# EVTSVT register map
Vendor: Texas Instruments
Peripheral module from a debugger description file (folder CC23x0R5).
Registers are 32-bit, access per field, reset 0x0 unless marked. A register's access mark holds for its fields unless they carry their own. Offsets are as the file gives them; lines under a group give offsets from that group; [hi:lo] are bit positions; {n}, {i} and the like mark numbered series; 'fields as' and 'values as' point back to an identical list; <NAME> marks a mode.

## EVTSVT — This is top module of SVT Event Fabric
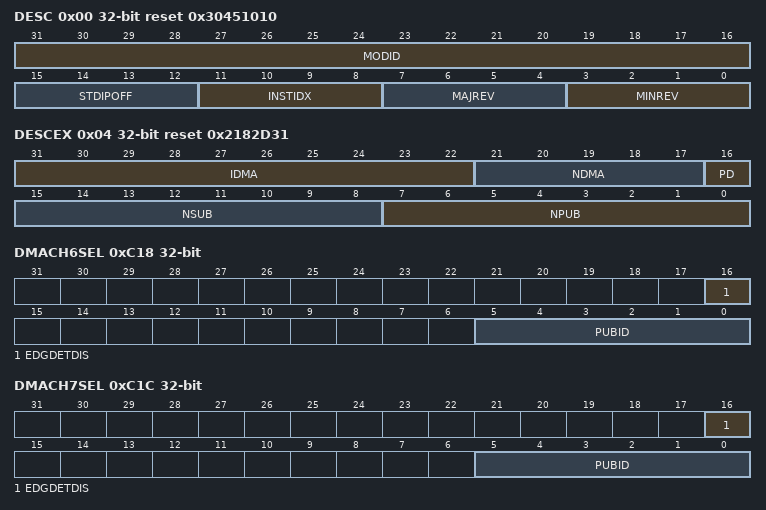
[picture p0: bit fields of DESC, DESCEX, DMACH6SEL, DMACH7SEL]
0x00 DESC ro reset 0x30451010 — Description This register provides IP module ID, revision information, instance index and standard MMR registers offset.
  [31:16] MODID — Module identifier used to uniquely identify this IP.
  [15:12] STDIPOFF — Standard IP MMR block offset. Standard IP MMRs are the set of from aggregated IRQ registers till DTB. 0: Standard IP MMRs do not exist 0x1-0xF: Standard IP MMRs begin at offset of (64*STDIPOFF from the base IP address)
  [11:8] INSTIDX — IP Instance ID number. If multiple instances of IP exist in the device, this field can identify the instance number (0-15).
  [7:4] MAJREV — Major revision of IP (0-15).
  [3:0] MINREV — Minor revision of IP (0-15).
0x04 DESCEX ro reset 0x2182D31 — Extended Description This register provides configuration details of the IP to software drivers and end users.
  [31:22] IDMA — Number of DMA input channels
  [21:17] NDMA — Number of DMA output channels
  [16] PD — Power Domain. 0 : SVT 1 : ULL
  [15:8] NSUB — Number of Subscribers
  [7:0] NPUB — Number of Publishers
0x64 DTB — Digital test bus control This register can be used to bring out IP internal signals to the pads for observation. 16 signals can be observed per select value.
  [1:0] SEL rw — Digital test bus selection mux control. Non-zero select values output a 16 bit selected group of signals per value.
    0=DIS (All 16 observation signals are set to zero.)
0x400 NMISEL — Output Selection for CPU NMI Exception
  [5:0] PUBID rw — Read/write selection value. Writing any other value than values defined by a ENUM may result in undefined behavior.
    57=LGPT3_ADC (LGPT3 ADC trigger event, controlled by LGPT3:ADCTRG setting); 56=LGPT3_DMA (LGPT3 DMA request event, controlled by LGPT3:DMA setting); 55=LGPT3_COMB (LGPT3 combined interrupt, interrupt flags are found here LGPT3:MIS); 54=LGPT3C2 (LGPT3 compare/capture output event 2, controlled by LGPT3:C2CFG setting); 53=LGPT3C1 (LGPT3 compare/capture output event 1, controlled by LGPT3:C1CFG setting); 52=LGPT3C0 (LGPT3 compare/capture output event 0, controlled by LGPT3:C0CFG setting); 51=LGPT2_ADC (LGPT2 ADC trigger event, controlled by LGPT2:ADCTRG setting); 50=LGPT2_DMA (LGPT2 DMA request event, controlled by LGPT2:DMA setting); 49=LGPT2_COMB (LGPT2 combined interrupt, interrupt flags are found here LGPT2:MIS); 48=LGPT2C2 (LGPT0 compare/capture output event 2, controlled by LGPT2:C2CFG setting); 47=LGPT2C1 (LGPT2 compare/capture output event 1, controlled by LGPT2:C1CFG setting); 46=LGPT2C0 (LGPT2 compare/capture output event 0, controlled by LGPT2:C0CFG setting); 44=LRFD_EVT2 (LRFD interrupt to SYSTIM, controlled by LRFDDBELL:SYSTIMOEV.SRC2); 43=LRFD_EVT1 (LRFD interrupt to SYSTIM, controlled by LRFDDBELL:SYSTIMOEV.SRC1); 42=LRFD_EVT0 (LRFD interrupt to SYSTIM, controlled by LRFDDBELL:SYSTIMOEV.SRC0); 41=LGPT1_ADC (LGPT1 ADC trigger event, controlled by LGPT1:ADCTRG setting); 40=LGPT1_DMA (LGPT1 DMA request event, controlled by LGPT1:DMA setting); 39=LGPT1C2 (LGPT1 compare/capture output event 2, controlled by LGPT1:C2CFG setting); 38=LGPT1C1 (LGPT1 compare/capture output event 1, controlled by LGPT1:C1CFG setting); 37=LGPT1C0 (LGPT1 compare/capture output event 0, controlled by LGPT1:C0CFG setting); 36=LGPT0_ADC (LGPT0 ADC trigger event, controlled by LGPT0:ADCTRG setting); 35=LGPT0_DMA (LGPT0 DMA request event, controlled by LGPT0:DMA setting); 34=LGPT0C2 (LGPT0 compare/capture output event 2, controlled by LGPT0:C2CFG setting); 33=LGPT0C1 (LGPT0 compare/capture output event 1, controlled by LGPT0:C1CFG setting); 32=LGPT0C0 (LGPT0 compare/capture output event 0, controlled by LGPT0:C0CFG setting); {v}=SYSTIM{v-27} (SYSTIM Channel {v-27} event, event flag is SYSTIM:MIS.EVT{v-27}) (v=27..31); 26=SYSTIM_LT (SYSTIM interrupt driven by synchronizing LFTICK signal to SVT clock); 25=SYSTIM_HB (SYSTIM heartbeat, can be set by SYSTIM:TIMEBIT); 24=I2C0_IRQ (Interrupt event from I2C0, interrupt flags can be found here I2C0:MIS); 23=UART0_COMB (UART0 combined interrupt, interrupt flags are found here UART0:MIS); 22=AES_COMB (AES accelerator combined interrupt request, interrupt flags can be found here AES:MIS); 21=DMA_ERR (DMA bus error, corresponds to DMA:ERROR.STATUS); 20=DMA_DONE_COMB (DMA combined done interrupt, corresponding flags can be found here DMA:REQDONE); 19=LGPT1_COMB (LGPT1 combined interrupt, interrupt flags are found here LGPT1:MIS); 18=LGPT0_COMB (LGPT0 combined interrupt, interrupt flags are found here LGPT0:MIS); 17=ADC_EVT (ADC general published event, interrupt flags can be found here ADC:MIS1); 16=ADC_COMB (ADC combined interrupt request, interrupt flags can be found here ADC:MIS0); 15=SPI0_COMB (SPI0 combined interrupt request, interrupt flags can be found here SPI0:MIS); 14=LRFD_IRQ2 (LRFD combined event, interrupt flags can be found here LRFDDBELL:MIS2); 13=LRFD_IRQ1 (LRFD combined event, interrupt flags can be found here LRFDDBELL:MIS1); 12=LRFD_IRQ0 (LRFD combined event, interrupt flags can be found here LRFDDBELL:MIS0); 11=FLASH_IRQ (NoWrapper Flash interrupt indicating that the flash operation has completed, interrupt flags can be found here FLASH:MIS); 10=GPIO_EVT (GPIO generic published event, controlled by GPIO:EVTCFG); 9=GPIO_COMB (GPIO combined wake up interrupt, interrupt flags can be found here GPIO:MIS); 8=SYSTIM_COMB (SYSTIM combined interrupt, interrupt flags are found here SYSTIM:MIS); 1=AON_NMI_SEL (Selects an AON_NMI source, controlled by EVTULL:NMISEL); 0=NONE (Always inactive)
0x404 CPUIRQ0SEL — Output Selection for CPU Interrupt CPUIRQ0
  [5:0] PUBID rw — Read/write selection value. Writing any other value than values defined by a ENUM may result in undefined behavior.
    57=LGPT3_ADC (LGPT3 ADC trigger event, controlled by LGPT3:ADCTRG setting); 56=LGPT3_DMA (LGPT3 DMA request event, controlled by LGPT3:DMA setting); 55=LGPT3_COMB (LGPT3 combined interrupt, interrupt flags are found here LGPT3:MIS); 54=LGPT3C2 (LGPT3 compare/capture output event 2, controlled by LGPT3:C2CFG setting); 53=LGPT3C1 (LGPT3 compare/capture output event 1, controlled by LGPT3:C1CFG setting); 52=LGPT3C0 (LGPT3 compare/capture output event 0, controlled by LGPT3:C0CFG setting); 51=LGPT2_ADC (LGPT2 ADC trigger event, controlled by LGPT2:ADCTRG setting); 50=LGPT2_DMA (LGPT2 DMA request event, controlled by LGPT2:DMA setting); 49=LGPT2_COMB (LGPT2 combined interrupt, interrupt flags are found here LGPT2:MIS); 48=LGPT2C2 (LGPT0 compare/capture output event 2, controlled by LGPT2:C2CFG setting); 47=LGPT2C1 (LGPT2 compare/capture output event 1, controlled by LGPT2:C1CFG setting); 46=LGPT2C0 (LGPT2 compare/capture output event 0, controlled by LGPT2:C0CFG setting); 44=LRFD_EVT2 (LRFD interrupt to SYSTIM, controlled by LRFDDBELL:SYSTIMOEV.SRC2); 43=LRFD_EVT1 (LRFD interrupt to SYSTIM, controlled by LRFDDBELL:SYSTIMOEV.SRC1); 42=LRFD_EVT0 (LRFD interrupt to SYSTIM, controlled by LRFDDBELL:SYSTIMOEV.SRC0); 41=LGPT1_ADC (LGPT1 ADC trigger event, controlled by LGPT1:ADCTRG setting); 40=LGPT1_DMA (LGPT1 DMA request event, controlled by LGPT1:DMA setting); 39=LGPT1C2 (LGPT1 compare/capture output event 2, controlled by LGPT1:C2CFG setting); 38=LGPT1C1 (LGPT1 compare/capture output event 1, controlled by LGPT1:C1CFG setting); 37=LGPT1C0 (LGPT1 compare/capture output event 0, controlled by LGPT1:C0CFG setting); 36=LGPT0_ADC (LGPT0 ADC trigger event, controlled by LGPT0:ADCTRG setting); 35=LGPT0_DMA (LGPT0 DMA request event, controlled by LGPT0:DMA setting); 34=LGPT0C2 (LGPT0 compare/capture output event 2, controlled by LGPT0:C2CFG setting); 33=LGPT0C1 (LGPT0 compare/capture output event 1, controlled by LGPT0:C1CFG setting); 32=LGPT0C0 (LGPT0 compare/capture output event 0, controlled by LGPT0:C0CFG setting); {v}=SYSTIM{v-27} (SYSTIM Channel {v-27} event, event flag is SYSTIM:MIS.EVT{v-27}) (v=27..31); 26=SYSTIM_LT (SYSTIM interrupt driven by synchronizing LFTICK signal to SVT clock); 25=SYSTIM_HB (SYSTIM heartbeat, can be set by SYSTIM:TIMEBIT); 24=I2C0_IRQ (Interrupt event from I2C0, interrupt flags can be found here I2C0:MIS); 23=UART0_COMB (UART0 combined interrupt, interrupt flags are found here UART0:MIS); 22=AES_COMB (AES accelerator combined interrupt request, interrupt flags can be found here AES:MIS); 21=DMA_ERR (DMA bus error, corresponds to DMA:ERROR.STATUS); 20=DMA_DONE_COMB (DMA combined done interrupt, corresponding flags can be found here DMA:REQDONE); 19=LGPT1_COMB (LGPT1 combined interrupt, interrupt flags are found here LGPT1:MIS); 18=LGPT0_COMB (LGPT0 combined interrupt, interrupt flags are found here LGPT0:MIS); 17=ADC_EVT (ADC general published event, interrupt flags can be found here ADC:MIS1); 16=ADC_COMB (ADC combined interrupt request, interrupt flags can be found here ADC:MIS0); 15=SPI0_COMB (SPI0 combined interrupt request, interrupt flags can be found here SPI0:MIS); 14=LRFD_IRQ2 (LRFD combined event, interrupt flags can be found here LRFDDBELL:MIS2); 13=LRFD_IRQ1 (LRFD combined event, interrupt flags can be found here LRFDDBELL:MIS1); 12=LRFD_IRQ0 (LRFD combined event, interrupt flags can be found here LRFDDBELL:MIS0); 11=FLASH_IRQ (NoWrapper Flash interrupt indicating that the flash operation has completed, interrupt flags can be found here FLASH:MIS); 10=GPIO_EVT (GPIO generic published event, controlled by GPIO:EVTCFG); 9=GPIO_COMB (GPIO combined wake up interrupt, interrupt flags can be found here GPIO:MIS); 8=SYSTIM_COMB (SYSTIM combined interrupt, interrupt flags are found here SYSTIM:MIS); 7=AON_IOC_COMB (IOC synchronous combined event, controlled by IOC:EVTCFG); 6=AON_LPMCMP_IRQ (AON LPCMP interrupt, controlled by SYS0:LPCMPCFG); 5=AON_DBG_COMB (DebugSS combined interrupt, interrupt flags can be found here DBGSS:MIS); 4=AON_RTC_COMB (AON_RTC event, controlled by the RTC:IMASK setting); 3=AON_CKM_COMB (CKMD combined interrupt request, interrupt flags can be found here CKMD:MIS); 2=AON_PMU_COMB (PMU combined interrupt request for BATMON, interrupt flags can be found here PMUD:EVENT); 0=NONE (Always inactive)
0x408 CPUIRQ1SEL — Output Selection for CPU Interrupt CPUIRQ1
  fields as CPUIRQ0SEL
{0x404+4i} CPUIRQ{i}SEL (i=2..4) — Output Selection for CPU Interrupt CPUIRQ{i}
  [5:0] PUBID rw — Read/write selection value. Writing any other value than values defined by a ENUM may result in undefined behavior.
    55=LGPT3_COMB (LGPT3 combined interrupt, interrupt flags are found here LGPT3:MIS); 49=LGPT2_COMB (LGPT2 combined interrupt, interrupt flags are found here LGPT2:MIS); 24=I2C0_IRQ (Interrupt event from I2C0, interrupt flags can be found here I2C0:MIS); 23=UART0_COMB (UART0 combined interrupt, interrupt flags are found here UART0:MIS); 22=AES_COMB (AES accelerator combined interrupt request, interrupt flags can be found here AES:MIS); 21=DMA_ERR (DMA bus error, corresponds to DMA:ERROR.STATUS); 20=DMA_DONE_COMB (DMA combined done interrupt, corresponding flags can be found here DMA:REQDONE); 19=LGPT1_COMB (LGPT1 combined interrupt, interrupt flags are found here LGPT1:MIS); 18=LGPT0_COMB (LGPT0 combined interrupt, interrupt flags are found here LGPT0:MIS); 16=ADC_COMB (ADC combined interrupt request, interrupt flags can be found here ADC:MIS0); 15=SPI0_COMB (SPI0 combined interrupt request, interrupt flags can be found here SPI0:MIS); 14=LRFD_IRQ2 (LRFD combined event, interrupt flags can be found here LRFDDBELL:MIS2); 13=LRFD_IRQ1 (LRFD combined event, interrupt flags can be found here LRFDDBELL:MIS1); 12=LRFD_IRQ0 (LRFD combined event, interrupt flags can be found here LRFDDBELL:MIS0); 11=FLASH_IRQ (NoWrapper Flash interrupt indicating that the flash operation has completed, interrupt flags can be found here FLASH:MIS); 9=GPIO_COMB (GPIO combined wake up interrupt, interrupt flags can be found here GPIO:MIS); 8=SYSTIM_COMB (SYSTIM combined interrupt, interrupt flags are found here SYSTIM:MIS); 7=AON_IOC_COMB (IOC synchronous combined event, controlled by IOC:EVTCFG); 6=AON_LPMCMP_IRQ (AON LPCMP interrupt, controlled by SYS0:LPCMPCFG); 5=AON_DBG_COMB (DebugSS combined interrupt, interrupt flags can be found here DBGSS:MIS); 4=AON_RTC_COMB (AON_RTC event, controlled by the RTC:IMASK setting); 3=AON_CKM_COMB (CKMD combined interrupt request, interrupt flags can be found here CKMD:MIS); 2=AON_PMU_COMB (PMU combined interrupt request for BATMON, interrupt flags can be found here PMUD:EVENT); 0=NONE (Always inactive)
0x418 CPUIRQ5SEL ro reset 0x9 — Output Selection for CPU Interrupt CPUIRQ5
  [5:0] PUBID — Read only selection value
    9=GPIO_COMB (GPIO combined wake up interrupt, interrupt flags can be found here GPIO:MIS)
0x41C CPUIRQ6SEL ro reset 0xC — Output Selection for CPU Interrupt CPUIRQ6
  [5:0] PUBID — Read only selection value
    12=LRFD_IRQ0 (LRFD combined event, interrupt flags can be found here LRFDDBELL:MIS0)
0x420 CPUIRQ7SEL ro reset 0xD — Output Selection for CPU Interrupt CPUIRQ7
  [5:0] PUBID — Read only selection value
    13=LRFD_IRQ1 (LRFD combined event, interrupt flags can be found here LRFDDBELL:MIS1)
0x424 CPUIRQ8SEL ro reset 0x14 — Output Selection for CPU Interrupt CPUIRQ8
  [5:0] PUBID — Read only selection value
    20=DMA_DONE_COMB (DMA combined done interrupt, corresponding flags can be found here DMA:REQDONE)
0x428 CPUIRQ9SEL ro reset 0x16 — Output Selection for CPU Interrupt CPUIRQ9
  [5:0] PUBID — Read only selection value
    22=AES_COMB (AES accelerator combined interrupt request, interrupt flags can be found here AES:MIS)
0x42C CPUIRQ10SEL ro reset 0xF — Output Selection for CPU Interrupt CPUIRQ10
  [5:0] PUBID — Read only selection value
    15=SPI0_COMB (SPI0 combined interrupt request, interrupt flags can be found here SPI0:MIS)
0x430 CPUIRQ11SEL ro reset 0x17 — Output Selection for CPU Interrupt CPUIRQ11
  [5:0] PUBID — Read only selection value
    23=UART0_COMB (UART0 combined interrupt, interrupt flags are found here UART0:MIS)
0x434 CPUIRQ12SEL ro reset 0x18 — Output Selection for CPU Interrupt CPUIRQ12
  [5:0] PUBID — Read only selection value
    24=I2C0_IRQ (Interrupt event from I2C0, interrupt flags can be found here I2C0:MIS)
0x438 CPUIRQ13SEL ro reset 0x12 — Output Selection for CPU Interrupt CPUIRQ13
  [5:0] PUBID — Read only selection value
    18=LGPT0_COMB (LGPT0 combined interrupt, interrupt flags are found here LGPT0:MIS)
0x43C CPUIRQ14SEL ro reset 0x13 — Output Selection for CPU Interrupt CPUIRQ14
  [5:0] PUBID — Read only selection value
    19=LGPT1_COMB (LGPT1 combined interrupt, interrupt flags are found here LGPT1:MIS)
0x440 CPUIRQ15SEL ro reset 0x10 — Output Selection for CPU Interrupt CPUIRQ15
  [5:0] PUBID — Read only selection value
    16=ADC_COMB (ADC combined interrupt request, interrupt flags can be found here ADC:MIS0)
0x444 CPUIRQ16SEL — Output Selection for CPU Interrupt CPUIRQ16
  fields as CPUIRQ0SEL
0x448 CPUIRQ17SEL ro reset 0x31 — Output Selection for CPU Interrupt CPUIRQ17
  [5:0] PUBID — Read only selection value
    49=LGPT2_COMB (LGPT2 combined interrupt, interrupt flags are found here LGPT2:MIS)
0x44C CPUIRQ18SEL ro reset 0x37 — Output Selection for CPU Interrupt CPUIRQ18
  [5:0] PUBID — Read only selection value
    55=LGPT3_COMB (LGPT3 combined interrupt, interrupt flags are found here LGPT3:MIS)
0x450 SYSTIMC0SEL ro reset 0x4 — Output Selection for SYSTIMC0
  [5:0] PUBID — Read only selection value
    4=AON_RTC_COMB (AON_RTC event, controlled by the RTC:IMASK setting)
0x454 SYSTIMC1SEL — Output Selection for SYSTIMC1
  fields as CPUIRQ0SEL
0x458 SYSTIMC2SEL ro reset 0x2A — Output Selection for SYSTIMC2
  [5:0] PUBID — Read only selection value
    42=LRFD_EVT0 (LRFD interrupt to SYSTIM, controlled by LRFDDBELL:SYSTIMOEV.SRC0)
0x45C SYSTIMC3SEL ro reset 0x2B — Output Selection for SYSTIMC3
  [5:0] PUBID — Read only selection value
    43=LRFD_EVT1 (LRFD interrupt to SYSTIM, controlled by LRFDDBELL:SYSTIMOEV.SRC1)
0x460 SYSTIMC4SEL ro reset 0x2C — Output Selection for SYSTIMC4
  [5:0] PUBID — Read only selection value
    44=LRFD_EVT2 (LRFD interrupt to SYSTIM, controlled by LRFDDBELL:SYSTIMOEV.SRC2)
0x464 ADCTRGSEL — Output Selection for ADCTRG
  fields as CPUIRQ0SEL
0x468 LGPTSYNCSEL — Output Selection for LGPTSYNC
  fields as CPUIRQ0SEL
{0x46C+0x10*i} LGPT{i}IN0SEL (i=0..3) — Output Selection for LGPT{i}IN0
  fields as CPUIRQ0SEL
{0x470+0x10*i} LGPT{i}IN1SEL (i=0..3) — Output Selection for LGPT{i}IN1
  [5:0] PUBID rw — Read/write selection value. Writing any other value than values defined by a ENUM may result in undefined behavior.
    57=LGPT3_ADC (LGPT3 ADC trigger event, controlled by LGPT3:ADCTRG setting); 56=LGPT3_DMA (LGPT3 DMA request event, controlled by LGPT3:DMA setting); 54=LGPT3C2 (LGPT3 compare/capture output event 2, controlled by LGPT3:C2CFG setting); 53=LGPT3C1 (LGPT3 compare/capture output event 1, controlled by LGPT3:C1CFG setting); 52=LGPT3C0 (LGPT3 compare/capture output event 0, controlled by LGPT3:C0CFG setting); 51=LGPT2_ADC (LGPT2 ADC trigger event, controlled by LGPT2:ADCTRG setting); 50=LGPT2_DMA (LGPT2 DMA request event, controlled by LGPT2:DMA setting); 48=LGPT2C2 (LGPT0 compare/capture output event 2, controlled by LGPT2:C2CFG setting); 47=LGPT2C1 (LGPT2 compare/capture output event 1, controlled by LGPT2:C1CFG setting); 46=LGPT2C0 (LGPT2 compare/capture output event 0, controlled by LGPT2:C0CFG setting); 44=LRFD_EVT2 (LRFD interrupt to SYSTIM, controlled by LRFDDBELL:SYSTIMOEV.SRC2); 43=LRFD_EVT1 (LRFD interrupt to SYSTIM, controlled by LRFDDBELL:SYSTIMOEV.SRC1); 42=LRFD_EVT0 (LRFD interrupt to SYSTIM, controlled by LRFDDBELL:SYSTIMOEV.SRC0); 41=LGPT1_ADC (LGPT1 ADC trigger event, controlled by LGPT1:ADCTRG setting); 40=LGPT1_DMA (LGPT1 DMA request event, controlled by LGPT1:DMA setting); 39=LGPT1C2 (LGPT1 compare/capture output event 2, controlled by LGPT1:C2CFG setting); 38=LGPT1C1 (LGPT1 compare/capture output event 1, controlled by LGPT1:C1CFG setting); 37=LGPT1C0 (LGPT1 compare/capture output event 0, controlled by LGPT1:C0CFG setting); 36=LGPT0_ADC (LGPT0 ADC trigger event, controlled by LGPT0:ADCTRG setting); 35=LGPT0_DMA (LGPT0 DMA request event, controlled by LGPT0:DMA setting); 34=LGPT0C2 (LGPT0 compare/capture output event 2, controlled by LGPT0:C2CFG setting); 33=LGPT0C1 (LGPT0 compare/capture output event 1, controlled by LGPT0:C1CFG setting); 32=LGPT0C0 (LGPT0 compare/capture output event 0, controlled by LGPT0:C0CFG setting); {v}=SYSTIM{v-27} (SYSTIM Channel {v-27} event, event flag is SYSTIM:MIS.EVT{v-27}) (v=27..31); 26=SYSTIM_LT (SYSTIM interrupt driven by synchronizing LFTICK signal to SVT clock); 25=SYSTIM_HB (SYSTIM heartbeat, can be set by SYSTIM:TIMEBIT); 17=ADC_EVT (ADC general published event, interrupt flags can be found here ADC:MIS1); 10=GPIO_EVT (GPIO generic published event, controlled by GPIO:EVTCFG); 0=NONE (Always inactive)
{0x474+0x10*i} LGPT{i}IN2SEL (i=0..3) — Output Selection for LGPT{i}IN2
  fields as LGPT0IN1SEL
{0x478+0x10*i} LGPT{i}TENSEL (i=0..3) — Output Selection for LGPT{i}TEN
  fields as LGPT0IN1SEL
0x4AC LRFDIN0SEL ro reset 0x1D — Output Selection for LRFDIN0
  [5:0] PUBID — Read only selection value
    29=SYSTIM2 (SYSTIM Channel 2 event, event flag is SYSTIM:MIS.EVT2)
0x4B0 LRFDIN1SEL ro reset 0x1E — Output Selection for LRFDIN1
  [5:0] PUBID — Read only selection value
    30=SYSTIM3 (SYSTIM Channel 3 event, event flag is SYSTIM:MIS.EVT3)
0x4B4 LRFDIN2SEL ro reset 0x1F — Output Selection for LRFDIN2
  [5:0] PUBID — Read only selection value
    31=SYSTIM4 (SYSTIM Channel 4 event, event flag is SYSTIM:MIS.EVT4)
0xC00 DMACH0SEL — Output Selection for DMA CH0
  [2:0] IPID rw — Read/write selection value. Writing any other value than values defined by a ENUM may result in undefined behavior.
    7=UART0RXTRG (Selects uart0rxtrg as channel source); 0=SPI0TXTRG (Selects spi0txtrg as channel source)
0xC04 DMACH1SEL — Output Selection for DMA CH1
  [2:0] IPID rw — Read/write selection value. Writing any other value than values defined by a ENUM may result in undefined behavior.
    6=UART0TXTRG (Selects uart0txtrg as channel source); 1=SPI0RXTRG (Selects spi0rxtrg as channel source)
0xC08 DMACH2SEL — Output Selection for DMA CH2
  [2:0] IPID rw — Read/write selection value. Writing any other value than values defined by a ENUM may result in undefined behavior.
    6=UART0TXTRG (Selects uart0txtrg as channel source)
0xC0C DMACH3SEL — Output Selection for DMA CH3
  [2:0] IPID rw — Read/write selection value. Writing any other value than values defined by a ENUM may result in undefined behavior.
    7=UART0RXTRG (Selects uart0rxtrg as channel source); 5=ADC0TRG (Selects adc0trg as channel source)
0xC10 DMACH4SEL — Output Selection for DMA CH4
  [2:0] IPID rw — Read/write selection value. Writing any other value than values defined by a ENUM may result in undefined behavior.
    3=LAESTRGA (Selects laestrga as channel source)
0xC14 DMACH5SEL — Output Selection for DMA CH5
  [2:0] IPID rw — Read/write selection value. Writing any other value than values defined by a ENUM may result in undefined behavior.
    5=ADC0TRG (Selects adc0trg as channel source); 4=LAESTRGB (Selects laestrgb as channel source)
0xC18 DMACH6SEL — Output Selection for DMA CH6
  [16] EDGDETDIS rw — Edge detect disable. 0: Enabled. 1: Disabled
  [5:0] PUBID rw — Read/write selection value. Writing any other value than values defined by a ENUM may result in undefined behavior.
    values as CPUIRQ0SEL.PUBID
0xC1C DMACH7SEL — Output Selection for DMA CH7
  fields as DMACH6SEL
